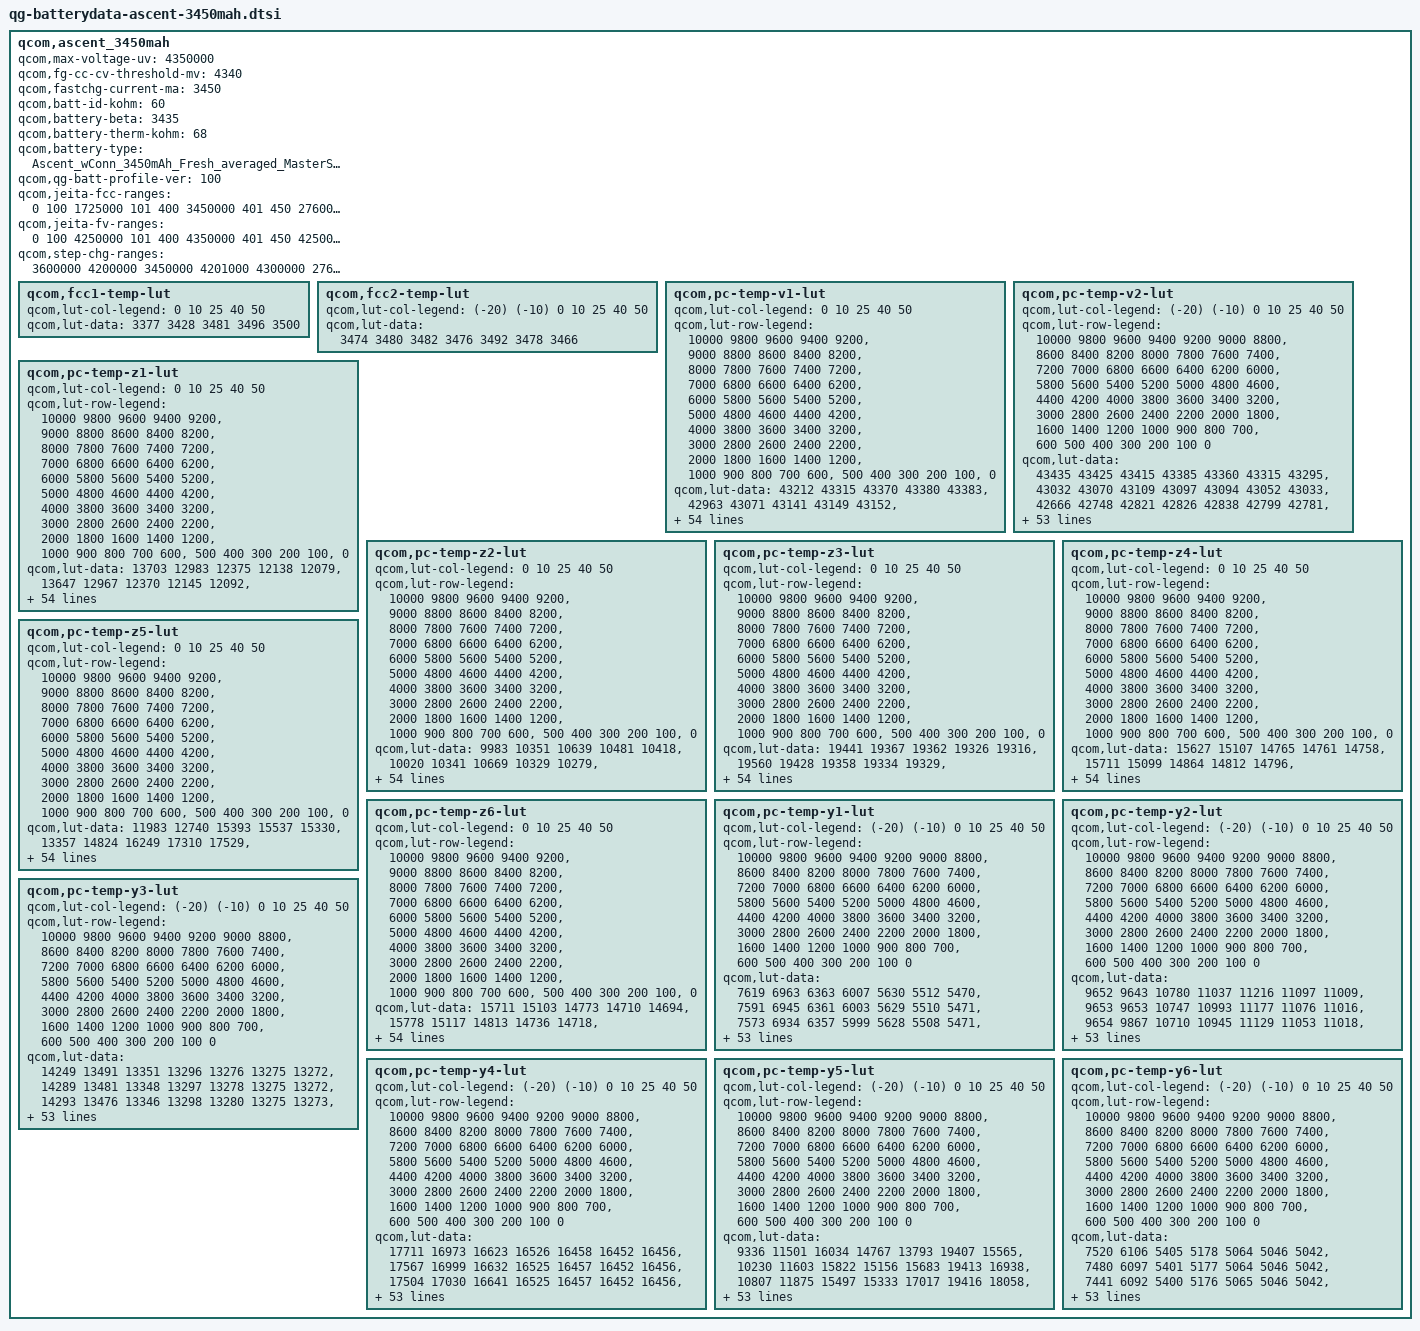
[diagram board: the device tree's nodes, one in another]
/* Copyright (c) 2018, The Linux Foundation. All rights reserved.
 *
 * This program is free software; you can redistribute it and/or modify
 * it under the terms of the GNU General Public License version 2 and
 * only version 2 as published by the Free Software Foundation.
 *
 * This program is distributed in the hope that it will be useful,
 * but WITHOUT ANY WARRANTY; without even the implied warranty of
 * MERCHANTABILITY or FITNESS FOR A PARTICULAR PURPOSE.  See the
 * GNU General Public License for more details.
 */

qcom,ascent_3450mah {
	/* Ascent_wConn_3450mAh_Fresh_averaged_MasterSlave_Feb7th2018 */
	qcom,max-voltage-uv = <4350000>;
	qcom,fg-cc-cv-threshold-mv = <4340>;
	qcom,fastchg-current-ma = <3450>;
	qcom,batt-id-kohm = <60>;
	qcom,battery-beta = <3435>;
	qcom,battery-therm-kohm = <68>;
	qcom,battery-type =
		"Ascent_wConn_3450mAh_Fresh_averaged_MasterSlave_Feb7th2018";
	qcom,qg-batt-profile-ver = <100>;

	qcom,jeita-fcc-ranges = <0   100  1725000
				101  400  3450000
				401  450  2760000>;
	qcom,jeita-fv-ranges = <0   100  4250000
				101 400  4350000
				401 450  4250000>;
	qcom,step-chg-ranges = <3600000  4200000  3450000
				4201000  4300000  2760000
				4301000  4350000  2070000>;

	qcom,fcc1-temp-lut {
		qcom,lut-col-legend = <0 10 25 40 50>;
		qcom,lut-data = <3377 3428 3481 3496 3500>;
	};

	qcom,fcc2-temp-lut {
		qcom,lut-col-legend = <(-20) (-10) 0 10 25 40 50>;
		qcom,lut-data = <3474 3480 3482 3476 3492 3478 3466>;
	};

	qcom,pc-temp-v1-lut {
		qcom,lut-col-legend = <0 10 25 40 50>;
		qcom,lut-row-legend = <10000 9800 9600 9400 9200>,
			<9000 8800 8600 8400 8200>,
			<8000 7800 7600 7400 7200>,
			<7000 6800 6600 6400 6200>,
			<6000 5800 5600 5400 5200>,
			<5000 4800 4600 4400 4200>,
			<4000 3800 3600 3400 3200>,
			<3000 2800 2600 2400 2200>,
			<2000 1800 1600 1400 1200>,
			<1000 900 800 700 600>,
			<500 400 300 200 100>,
			<0>;
		qcom,lut-data = <43212 43315 43370 43380 43383>,
			<42963 43071 43141 43149 43152>,
			<42723 42832 42902 42916 42922>,
			<42488 42597 42662 42683 42693>,
			<42262 42367 42430 42454 42465>,
			<42043 42143 42202 42225 42238>,
			<41832 41924 41976 41999 42013>,
			<41624 41709 41754 41775 41791>,
			<41419 41497 41536 41556 41571>,
			<41220 41288 41322 41341 41355>,
			<41039 41091 41113 41132 41143>,
			<40866 40911 40916 40928 40936>,
			<40676 40732 40729 40729 40734>,
			<40449 40526 40541 40538 40541>,
			<40230 40302 40340 40351 40355>,
			<40061 40115 40146 40170 40176>,
			<39918 39974 39984 40002 40007>,
			<39787 39846 39843 39845 39846>,
			<39672 39712 39697 39690 39689>,
			<39560 39579 39548 39536 39538>,
			<39426 39419 39388 39376 39384>,
			<39271 39170 39192 39187 39198>,
			<39112 38928 38961 38960 38967>,
			<38934 38809 38788 38776 38775>,
			<38764 38736 38674 38650 38646>,
			<38660 38665 38581 38546 38539>,
			<38589 38587 38491 38448 38439>,
			<38533 38513 38408 38359 38347>,
			<38487 38444 38334 38278 38263>,
			<38448 38381 38265 38204 38187>,
			<38407 38323 38204 38138 38118>,
			<38364 38269 38149 38078 38055>,
			<38322 38219 38099 38026 37999>,
			<38284 38175 38053 37975 37942>,
			<38249 38137 38014 37930 37889>,
			<38211 38098 37974 37884 37834>,
			<38174 38061 37930 37831 37767>,
			<38129 38020 37882 37771 37691>,
			<38055 37954 37816 37698 37610>,
			<37946 37848 37718 37605 37524>,
			<37825 37726 37602 37497 37426>,
			<37689 37595 37474 37372 37301>,
			<37541 37451 37332 37231 37156>,
			<37372 37290 37178 37080 36999>,
			<37271 37162 37061 36964 36886>,
			<37191 37093 36992 36897 36819>,
			<37157 37064 36970 36870 36798>,
			<37128 37039 36949 36844 36770>,
			<37084 37007 36903 36788 36714>,
			<36927 36851 36683 36562 36488>,
			<36555 36481 36290 36180 36108>,
			<36071 35999 35771 35687 35620>,
			<35450 35376 35098 35050 34994>,
			<34604 34523 34174 34184 34150>,
			<33275 33138 32725 32851 32862>,
			<30000 30000 30000 30000 30000>;
	};

	qcom,pc-temp-v2-lut {
		qcom,lut-col-legend = <(-20) (-10) 0 10 25 40 50>;
		qcom,lut-row-legend = <10000 9800 9600 9400 9200 9000 8800>,
			<8600 8400 8200 8000 7800 7600 7400>,
			<7200 7000 6800 6600 6400 6200 6000>,
			<5800 5600 5400 5200 5000 4800 4600>,
			<4400 4200 4000 3800 3600 3400 3200>,
			<3000 2800 2600 2400 2200 2000 1800>,
			<1600 1400 1200 1000 900 800 700>,
			<600 500 400 300 200 100 0>;
		qcom,lut-data = <43435 43425 43415 43385 43360 43315 43295>,
			<43032 43070 43109 43097 43094 43052 43033>,
			<42666 42748 42821 42826 42838 42799 42781>,
			<42342 42462 42555 42571 42594 42557 42541>,
			<42053 42208 42308 42333 42361 42326 42312>,
			<41788 41968 42072 42101 42133 42099 42086>,
			<41531 41736 41844 41872 41904 41872 41860>,
			<41298 41516 41625 41649 41680 41649 41637>,
			<41128 41303 41405 41431 41460 41430 41419>,
			<41009 41100 41186 41217 41243 41215 41204>,
			<40843 40896 40979 41012 41034 41005 40994>,
			<40462 40694 40796 40826 40840 40802 40789>,
			<40004 40482 40616 40642 40648 40604 40590>,
			<39736 40220 40407 40432 40445 40411 40399>,
			<39556 39903 40175 40199 40233 40222 40214>,
			<39382 39636 39954 39996 40043 40042 40036>,
			<39187 39443 39759 39844 39886 39877 39868>,
			<39001 39272 39570 39700 39736 39717 39706>,
			<38839 39091 39370 39511 39573 39556 39547>,
			<38695 38908 39162 39283 39399 39396 39391>,
			<38574 38742 38973 39072 39208 39217 39217>,
			<38477 38591 38806 38886 38975 38988 38994>,
			<38393 38460 38655 38721 38760 38766 38771>,
			<38314 38358 38519 38585 38613 38613 38614>,
			<38242 38274 38396 38468 38496 38494 38494>,
			<38176 38201 38287 38362 38390 38388 38387>,
			<38117 38138 38189 38265 38294 38291 38288>,
			<38062 38080 38106 38177 38206 38202 38198>,
			<38006 38027 38039 38096 38126 38120 38114>,
			<37953 37980 37983 38021 38051 38044 38037>,
			<37900 37934 37935 37954 37984 37976 37967>,
			<37847 37889 37895 37891 37921 37915 37905>,
			<37795 37843 37856 37838 37862 37856 37846>,
			<37742 37795 37815 37799 37803 37790 37781>,
			<37690 37746 37774 37768 37746 37720 37707>,
			<37635 37692 37727 37728 37685 37643 37621>,
			<37574 37633 37677 37677 37620 37554 37517>,
			<37509 37568 37618 37617 37550 37465 37411>,
			<37441 37491 37546 37548 37475 37387 37327>,
			<37368 37404 37459 37466 37395 37313 37256>,
			<37292 37310 37360 37369 37301 37226 37174>,
			<37209 37206 37243 37246 37187 37117 37069>,
			<37119 37103 37111 37106 37050 36988 36945>,
			<37020 37005 36964 36946 36900 36839 36796>,
			<36901 36909 36860 36837 36818 36761 36712>,
			<36762 36808 36782 36769 36775 36718 36673>,
			<36671 36746 36740 36732 36741 36690 36651>,
			<36552 36670 36688 36684 36692 36649 36612>,
			<36386 36553 36594 36591 36575 36542 36528>,
			<36157 36329 36380 36368 36272 36271 36278>,
			<35824 35961 35991 35957 35796 35833 35867>,
			<35340 35436 35452 35401 35193 35271 35340>,
			<34648 34709 34745 34680 34409 34550 34676>,
			<33623 33672 33759 33677 33330 33585 33791>,
			<31758 31857 32191 32244 31867 32001 32517>,
			<27623 28160 28896 29014 27510 28586 29617>;
	};

	qcom,pc-temp-z1-lut {
		qcom,lut-col-legend = <0 10 25 40 50>;
		qcom,lut-row-legend = <10000 9800 9600 9400 9200>,
			<9000 8800 8600 8400 8200>,
			<8000 7800 7600 7400 7200>,
			<7000 6800 6600 6400 6200>,
			<6000 5800 5600 5400 5200>,
			<5000 4800 4600 4400 4200>,
			<4000 3800 3600 3400 3200>,
			<3000 2800 2600 2400 2200>,
			<2000 1800 1600 1400 1200>,
			<1000 900 800 700 600>,
			<500 400 300 200 100>,
			<0>;
		qcom,lut-data = <13703 12983 12375 12138 12079>,
			<13647 12967 12370 12145 12092>,
			<13621 12953 12363 12143 12093>,
			<13606 12942 12357 12142 12093>,
			<13594 12927 12349 12140 12093>,
			<13585 12916 12342 12137 12093>,
			<13577 12905 12339 12136 12092>,
			<13569 12898 12337 12135 12092>,
			<13560 12896 12337 12135 12091>,
			<13551 12895 12339 12135 12091>,
			<13540 12896 12342 12136 12091>,
			<13527 12899 12342 12136 12091>,
			<13512 12901 12342 12137 12093>,
			<13488 12896 12342 12139 12095>,
			<13469 12887 12343 12141 12097>,
			<13469 12883 12347 12144 12098>,
			<13473 12891 12352 12147 12101>,
			<13478 12904 12360 12151 12103>,
			<13489 12912 12369 12155 12106>,
			<13502 12919 12378 12160 12109>,
			<13514 12927 12387 12165 12113>,
			<13525 12937 12396 12171 12117>,
			<13538 12948 12404 12177 12122>,
			<13555 12957 12412 12184 12127>,
			<13572 12965 12422 12189 12131>,
			<13578 12971 12431 12195 12135>,
			<13580 12978 12440 12200 12139>,
			<13582 12985 12448 12206 12143>,
			<13594 12992 12456 12212 12147>,
			<13613 13004 12464 12218 12151>,
			<13625 13010 12472 12224 12156>,
			<13631 13010 12479 12230 12160>,
			<13632 13010 12486 12237 12165>,
			<13627 13015 12494 12244 12171>,
			<13618 13033 12505 12253 12177>,
			<13619 13047 12517 12262 12183>,
			<13629 13056 12529 12271 12190>,
			<13640 13065 12541 12280 12196>,
			<13647 13068 12553 12290 12203>,
			<13654 13070 12565 12301 12210>,
			<13663 13071 12577 12311 12217>,
			<13678 13085 12588 12322 12224>,
			<13694 13098 12598 12332 12232>,
			<13718 13107 12607 12344 12239>,
			<13717 13110 12621 12356 12248>,
			<13717 13111 12638 12367 12256>,
			<13693 13110 12640 12374 12262>,
			<13712 13131 12642 12382 12269>,
			<13714 13118 12659 12395 12280>,
			<13717 13140 12677 12408 12291>,
			<13717 13160 12678 12422 12303>,
			<13740 13166 12691 12436 12316>,
			<13739 13183 12711 12456 12332>,
			<13754 13201 12735 12479 12355>,
			<13754 13201 12735 12479 12355>,
			<13754 13201 12735 12479 12355>;
	};

	qcom,pc-temp-z2-lut {
		qcom,lut-col-legend = <0 10 25 40 50>;
		qcom,lut-row-legend = <10000 9800 9600 9400 9200>,
			<9000 8800 8600 8400 8200>,
			<8000 7800 7600 7400 7200>,
			<7000 6800 6600 6400 6200>,
			<6000 5800 5600 5400 5200>,
			<5000 4800 4600 4400 4200>,
			<4000 3800 3600 3400 3200>,
			<3000 2800 2600 2400 2200>,
			<2000 1800 1600 1400 1200>,
			<1000 900 800 700 600>,
			<500 400 300 200 100>,
			<0>;
		qcom,lut-data = <9983 10351 10639 10481 10418>,
			<10020 10341 10669 10329 10279>,
			<10051 10333 10528 10319 10282>,
			<10083 10331 10397 10312 10281>,
			<10100 10329 10358 10299 10263>,
			<10094 10325 10328 10285 10234>,
			<10081 10303 10324 10279 10227>,
			<10069 10281 10328 10277 10237>,
			<10058 10278 10330 10276 10251>,
			<10050 10280 10326 10276 10266>,
			<10044 10285 10321 10281 10280>,
			<10039 10298 10323 10288 10285>,
			<10038 10310 10324 10308 10284>,
			<10045 10309 10318 10321 10285>,
			<10054 10304 10304 10319 10295>,
			<10056 10302 10291 10314 10309>,
			<10056 10312 10297 10316 10321>,
			<10058 10329 10320 10326 10335>,
			<10070 10353 10339 10334 10341>,
			<10090 10386 10349 10339 10346>,
			<10111 10400 10358 10343 10354>,
			<10138 10396 10373 10334 10340>,
			<10157 10388 10395 10289 10270>,
			<10169 10381 10400 10243 10212>,
			<10178 10372 10354 10197 10174>,
			<10183 10364 10306 10161 10144>,
			<10190 10352 10304 10160 10141>,
			<10194 10341 10307 10170 10149>,
			<10185 10335 10310 10181 10158>,
			<10169 10332 10311 10196 10169>,
			<10165 10332 10314 10216 10183>,
			<10168 10343 10327 10238 10202>,
			<10171 10357 10356 10267 10226>,
			<10175 10368 10381 10298 10253>,
			<10180 10376 10405 10333 10288>,
			<10183 10384 10422 10367 10326>,
			<10186 10393 10431 10393 10358>,
			<10189 10403 10438 10416 10387>,
			<10187 10410 10442 10437 10405>,
			<10181 10419 10455 10461 10418>,
			<10175 10423 10465 10476 10426>,
			<10164 10407 10466 10476 10430>,
			<10152 10385 10468 10474 10428>,
			<10142 10373 10453 10473 10402>,
			<10064 10371 10455 10479 10389>,
			<10173 10285 10486 10517 10402>,
			<10003 10290 10490 10530 10416>,
			<10151 10295 10531 10566 10477>,
			<10255 10515 10588 10612 10540>,
			<10077 10376 10556 10524 10421>,
			<9948 10240 10480 10454 10314>,
			<9854 10122 10384 10398 10256>,
			<9640 9998 10319 10342 10182>,
			<9440 9830 10255 10261 10065>,
			<9440 9830 10255 10261 10065>,
			<9440 9830 10255 10261 10065>;
	};

	qcom,pc-temp-z3-lut {
		qcom,lut-col-legend = <0 10 25 40 50>;
		qcom,lut-row-legend = <10000 9800 9600 9400 9200>,
			<9000 8800 8600 8400 8200>,
			<8000 7800 7600 7400 7200>,
			<7000 6800 6600 6400 6200>,
			<6000 5800 5600 5400 5200>,
			<5000 4800 4600 4400 4200>,
			<4000 3800 3600 3400 3200>,
			<3000 2800 2600 2400 2200>,
			<2000 1800 1600 1400 1200>,
			<1000 900 800 700 600>,
			<500 400 300 200 100>,
			<0>;
		qcom,lut-data = <19441 19367 19362 19326 19316>,
			<19560 19428 19358 19334 19329>,
			<19615 19467 19373 19341 19335>,
			<19645 19480 19383 19346 19340>,
			<19658 19487 19385 19351 19344>,
			<19657 19488 19387 19354 19347>,
			<19657 19486 19386 19355 19348>,
			<19655 19483 19384 19354 19347>,
			<19651 19481 19382 19352 19346>,
			<19647 19479 19380 19350 19345>,
			<19645 19477 19378 19347 19344>,
			<19642 19470 19377 19345 19342>,
			<19642 19464 19374 19345 19342>,
			<19642 19464 19372 19344 19341>,
			<19643 19467 19372 19343 19338>,
			<19639 19467 19372 19342 19336>,
			<19626 19460 19371 19340 19334>,
			<19615 19450 19369 19338 19332>,
			<19604 19448 19368 19337 19330>,
			<19596 19446 19368 19337 19328>,
			<19597 19447 19369 19337 19326>,
			<19605 19452 19372 19340 19328>,
			<19612 19460 19378 19350 19341>,
			<19619 19462 19386 19357 19350>,
			<19626 19464 19394 19361 19353>,
			<19627 19466 19401 19364 19355>,
			<19626 19472 19400 19364 19355>,
			<19624 19480 19398 19362 19352>,
			<19620 19480 19395 19359 19349>,
			<19615 19476 19391 19356 19346>,
			<19611 19473 19388 19353 19343>,
			<19609 19469 19384 19350 19340>,
			<19606 19466 19381 19347 19336>,
			<19604 19463 19379 19343 19332>,
			<19601 19461 19377 19338 19327>,
			<19597 19458 19375 19335 19324>,
			<19592 19454 19373 19334 19325>,
			<19587 19451 19370 19334 19329>,
			<19584 19448 19368 19334 19330>,
			<19582 19446 19366 19334 19328>,
			<19579 19443 19364 19334 19326>,
			<19575 19441 19362 19334 19326>,
			<19571 19438 19360 19334 19327>,
			<19565 19434 19359 19336 19329>,
			<19361 19423 19353 19335 19328>,
			<19262 19382 19344 19323 19324>,
			<19263 19371 19336 19321 19317>,
			<19261 19361 19332 19317 19313>,
			<19261 19273 19326 19317 19309>,
			<19262 19274 19335 19327 19319>,
			<19263 19303 19337 19330 19324>,
			<19263 19274 19357 19333 19327>,
			<19266 19275 19361 19337 19335>,
			<19272 19280 19368 19349 19345>,
			<19272 19280 19368 19349 19345>,
			<19272 19280 19368 19349 19345>;
	};

	qcom,pc-temp-z4-lut {
		qcom,lut-col-legend = <0 10 25 40 50>;
		qcom,lut-row-legend = <10000 9800 9600 9400 9200>,
			<9000 8800 8600 8400 8200>,
			<8000 7800 7600 7400 7200>,
			<7000 6800 6600 6400 6200>,
			<6000 5800 5600 5400 5200>,
			<5000 4800 4600 4400 4200>,
			<4000 3800 3600 3400 3200>,
			<3000 2800 2600 2400 2200>,
			<2000 1800 1600 1400 1200>,
			<1000 900 800 700 600>,
			<500 400 300 200 100>,
			<0>;
		qcom,lut-data = <15627 15107 14765 14761 14758>,
			<15711 15099 14864 14812 14796>,
			<15693 15080 14843 14798 14788>,
			<15530 15036 14821 14778 14775>,
			<15355 14952 14794 14760 14761>,
			<15246 14887 14764 14740 14745>,
			<15155 14845 14741 14726 14731>,
			<15085 14812 14721 14713 14719>,
			<15031 14784 14710 14705 14711>,
			<14985 14760 14705 14700 14707>,
			<14938 14745 14702 14697 14705>,
			<14895 14735 14696 14693 14702>,
			<14876 14729 14689 14688 14699>,
			<14872 14730 14686 14684 14697>,
			<14869 14735 14686 14681 14694>,
			<14856 14737 14686 14680 14692>,
			<14830 14720 14682 14677 14689>,
			<14808 14702 14673 14672 14684>,
			<14790 14701 14669 14669 14681>,
			<14778 14706 14676 14670 14679>,
			<14782 14717 14687 14675 14677>,
			<14805 14815 14716 14690 14685>,
			<14835 14927 14778 14733 14726>,
			<14898 14927 14803 14755 14750>,
			<14965 14883 14774 14738 14735>,
			<14974 14842 14741 14715 14712>,
			<14963 14813 14728 14705 14703>,
			<14950 14789 14721 14700 14699>,
			<14932 14778 14717 14696 14696>,
			<14910 14771 14715 14693 14692>,
			<14892 14767 14713 14691 14688>,
			<14878 14766 14712 14688 14683>,
			<14867 14765 14712 14684 14677>,
			<14856 14764 14710 14681 14673>,
			<14847 14763 14709 14676 14668>,
			<14838 14761 14706 14673 14666>,
			<14826 14756 14703 14673 14669>,
			<14816 14748 14700 14674 14680>,
			<14809 14744 14697 14674 14683>,
			<14804 14742 14695 14673 14677>,
			<14797 14739 14693 14671 14673>,
			<14787 14730 14687 14667 14673>,
			<14774 14718 14678 14663 14675>,
			<14753 14708 14673 14662 14682>,
			<14897 14683 14660 14653 14674>,
			<14965 14689 14638 14630 14635>,
			<14964 14694 14635 14621 14624>,
			<14958 14699 14630 14614 14617>,
			<14951 14794 14633 14616 14620>,
			<14945 14795 14637 14644 14655>,
			<14957 14769 14642 14654 14664>,
			<14968 14805 14636 14660 14668>,
			<14977 14809 14655 14668 14668>,
			<14993 14817 14684 14674 14665>,
			<14993 14817 14684 14674 14665>,
			<14993 14817 14684 14674 14665>;
	};

	qcom,pc-temp-z5-lut {
		qcom,lut-col-legend = <0 10 25 40 50>;
		qcom,lut-row-legend = <10000 9800 9600 9400 9200>,
			<9000 8800 8600 8400 8200>,
			<8000 7800 7600 7400 7200>,
			<7000 6800 6600 6400 6200>,
			<6000 5800 5600 5400 5200>,
			<5000 4800 4600 4400 4200>,
			<4000 3800 3600 3400 3200>,
			<3000 2800 2600 2400 2200>,
			<2000 1800 1600 1400 1200>,
			<1000 900 800 700 600>,
			<500 400 300 200 100>,
			<0>;
		qcom,lut-data = <11983 12740 15393 15537 15330>,
			<13357 14824 16249 17310 17529>,
			<14286 16482 17811 18377 18523>,
			<14945 17642 19175 19223 19510>,
			<15486 18555 20024 20275 20513>,
			<15957 19327 20723 21346 21540>,
			<16368 19918 21568 22345 22519>,
			<16781 20541 22514 23454 23469>,
			<17187 21683 23120 24074 24236>,
			<17674 23224 23449 23971 24698>,
			<18442 24060 23713 23757 25052>,
			<19483 24549 23914 23816 25554>,
			<20437 24925 24207 24637 26312>,
			<21361 25257 24451 25542 26851>,
			<22105 25909 24697 26092 27021>,
			<22478 26475 25087 26614 27131>,
			<22735 27141 26348 27394 27470>,
			<23076 28081 28954 28566 28331>,
			<23809 29715 30229 29356 28825>,
			<24938 32251 30431 29724 28646>,
			<27176 33544 30446 29885 28135>,
			<31932 33025 28578 28445 26783>,
			<35226 31860 23567 23249 22747>,
			<36819 29994 21621 20580 20432>,
			<37874 26035 23092 21806 21763>,
			<37147 24128 25214 23841 23948>,
			<34993 26078 27156 25488 25430>,
			<32825 29127 29386 27105 26647>,
			<30980 31187 31134 28441 27481>,
			<29376 32887 32400 29515 28206>,
			<28873 34208 33430 30375 28775>,
			<28786 35400 34311 31101 29161>,
			<28801 36250 35051 31824 29873>,
			<28836 36325 35497 32045 30283>,
			<28862 36122 35938 31861 30590>,
			<28907 35854 36221 31646 31106>,
			<28980 35186 35497 31570 32686>,
			<29132 34291 33694 31549 35494>,
			<29670 33796 32315 31543 36261>,
			<30652 33516 31332 31469 34185>,
			<30992 33114 30388 31412 32325>,
			<29938 32130 29262 32046 32870>,
			<29033 30867 28327 33225 34089>,
			<28928 29512 27958 34867 35083>,
			<16971 28826 27177 35407 35456>,
			<11113 18542 25875 28236 38118>,
			<11084 16735 22486 31621 32274>,
			<11037 15601 21798 36765 39261>,
			<11035 11499 20071 40032 37713>,
			<11055 11574 22201 35765 26327>,
			<11017 12415 21829 29484 22484>,
			<10951 11419 39496 26044 20817>,
			<10890 11348 40899 24307 20580>,
			<10822 11392 37952 25288 21070>,
			<10822 11392 37952 25288 21070>,
			<10822 11392 37952 25288 21070>;
	};

	qcom,pc-temp-z6-lut {
		qcom,lut-col-legend = <0 10 25 40 50>;
		qcom,lut-row-legend = <10000 9800 9600 9400 9200>,
			<9000 8800 8600 8400 8200>,
			<8000 7800 7600 7400 7200>,
			<7000 6800 6600 6400 6200>,
			<6000 5800 5600 5400 5200>,
			<5000 4800 4600 4400 4200>,
			<4000 3800 3600 3400 3200>,
			<3000 2800 2600 2400 2200>,
			<2000 1800 1600 1400 1200>,
			<1000 900 800 700 600>,
			<500 400 300 200 100>,
			<0>;
		qcom,lut-data = <15711 15103 14773 14710 14694>,
			<15778 15117 14813 14736 14718>,
			<15776 15120 14809 14733 14717>,
			<15702 15106 14804 14728 14716>,
			<15620 15065 14793 14722 14713>,
			<15561 15031 14779 14715 14707>,
			<15508 15007 14768 14709 14701>,
			<15467 14987 14758 14703 14696>,
			<15435 14971 14751 14698 14692>,
			<15407 14959 14748 14695 14689>,
			<15379 14949 14746 14692 14687>,
			<15353 14940 14743 14689 14685>,
			<15339 14935 14739 14687 14684>,
			<15332 14935 14736 14685 14682>,
			<15326 14938 14737 14684 14680>,
			<15316 14939 14738 14683 14678>,
			<15302 14930 14736 14681 14676>,
			<15293 14921 14733 14679 14673>,
			<15289 14921 14732 14677 14671>,
			<15286 14926 14736 14678 14670>,
			<15291 14936 14744 14682 14669>,
			<15312 14986 14761 14691 14674>,
			<15338 15040 14795 14718 14702>,
			<15373 15042 14808 14732 14717>,
			<15408 15027 14802 14727 14713>,
			<15415 15016 14795 14720 14706>,
			<15414 15011 14791 14717 14702>,
			<15412 15007 14788 14714 14699>,
			<15408 15006 14786 14712 14697>,
			<15402 15004 14785 14710 14694>,
			<15399 15004 14784 14708 14691>,
			<15398 15005 14784 14706 14688>,
			<15397 15006 14784 14704 14684>,
			<15397 15009 14784 14701 14680>,
			<15398 15012 14784 14699 14677>,
			<15400 15015 14785 14696 14674>,
			<15402 15016 14785 14697 14677>,
			<15405 15017 14786 14699 14684>,
			<15410 15020 14787 14700 14687>,
			<15416 15026 14789 14702 14685>,
			<15423 15031 14791 14703 14683>,
			<15430 15034 14791 14703 14684>,
			<15437 15037 14791 14704 14687>,
			<15444 15040 14792 14706 14693>,
			<15425 15039 14789 14704 14690>,
			<15419 15030 14781 14691 14673>,
			<15424 15030 14778 14688 14665>,
			<15425 15032 14777 14685 14661>,
			<15431 15036 14780 14688 14662>,
			<15438 15047 14792 14708 14685>,
			<15458 15060 14801 14718 14695>,
			<15477 15072 14815 14726 14702>,
			<15501 15088 14835 14737 14710>,
			<15534 15114 14862 14753 14720>,
			<15534 15114 14862 14753 14720>,
			<15534 15114 14862 14753 14720>;
	};

	qcom,pc-temp-y1-lut {
		qcom,lut-col-legend = <(-20) (-10) 0 10 25 40 50>;
		qcom,lut-row-legend = <10000 9800 9600 9400 9200 9000 8800>,
			<8600 8400 8200 8000 7800 7600 7400>,
			<7200 7000 6800 6600 6400 6200 6000>,
			<5800 5600 5400 5200 5000 4800 4600>,
			<4400 4200 4000 3800 3600 3400 3200>,
			<3000 2800 2600 2400 2200 2000 1800>,
			<1600 1400 1200 1000 900 800 700>,
			<600 500 400 300 200 100 0>;
		qcom,lut-data = <7619 6963 6363 6007 5630 5512 5470>,
			<7591 6945 6361 6003 5629 5510 5471>,
			<7573 6934 6357 5999 5628 5508 5471>,
			<7563 6929 6354 5995 5627 5506 5471>,
			<7558 6928 6353 5992 5626 5505 5470>,
			<7556 6928 6357 5988 5625 5503 5470>,
			<7563 6934 6366 5985 5624 5502 5469>,
			<7573 6942 6374 5981 5624 5501 5467>,
			<7583 6939 6374 5982 5623 5500 5467>,
			<7616 6920 6366 5984 5624 5499 5467>,
			<7634 6910 6360 5985 5624 5498 5466>,
			<7600 6919 6357 5980 5623 5498 5466>,
			<7557 6931 6356 5973 5622 5498 5465>,
			<7560 6935 6362 5973 5622 5499 5465>,
			<7590 6938 6380 5978 5625 5500 5466>,
			<7605 6939 6390 5981 5628 5501 5467>,
			<7608 6942 6389 5985 5631 5501 5468>,
			<7612 6946 6387 5990 5634 5502 5469>,
			<7604 6943 6388 5989 5637 5503 5470>,
			<7584 6932 6391 5988 5639 5506 5471>,
			<7570 6929 6394 5987 5643 5508 5472>,
			<7557 6957 6397 5989 5647 5510 5473>,
			<7546 6985 6400 5994 5653 5513 5475>,
			<7543 6976 6405 6001 5658 5515 5478>,
			<7542 6942 6414 6012 5663 5518 5480>,
			<7542 6928 6418 6018 5668 5522 5483>,
			<7552 6934 6419 6019 5674 5525 5486>,
			<7565 6942 6418 6020 5681 5529 5488>,
			<7569 6951 6418 6021 5687 5533 5491>,
			<7568 6972 6418 6023 5692 5537 5493>,
			<7564 6978 6418 6025 5698 5541 5497>,
			<7549 6971 6422 6028 5705 5545 5500>,
			<7534 6961 6425 6032 5712 5550 5504>,
			<7531 6947 6422 6038 5720 5554 5507>,
			<7529 6929 6416 6048 5727 5559 5509>,
			<7527 6925 6416 6055 5734 5563 5512>,
			<7537 6932 6428 6059 5741 5569 5516>,
			<7548 6939 6438 6062 5748 5575 5522>,
			<7546 6939 6433 6063 5757 5580 5526>,
			<7534 6942 6422 6064 5767 5585 5529>,
			<7527 6944 6417 6067 5775 5591 5533>,
			<7526 6946 6416 6077 5783 5596 5537>,
			<7530 6941 6418 6083 5787 5603 5541>,
			<7568 6923 6429 6090 5790 5610 5546>,
			<7559 6953 6428 6086 5808 5622 5555>,
			<7568 6932 6433 6091 5813 5631 5561>,
			<7570 6928 6433 6099 5818 5635 5565>,
			<7608 6933 6442 6113 5834 5640 5567>,
			<7652 6932 6430 6105 5835 5645 5571>,
			<7693 6936 6436 6106 5848 5654 5578>,
			<7737 6965 6440 6099 5858 5666 5585>,
			<7770 6990 6464 6110 5873 5684 5600>,
			<7830 7027 6445 6123 5887 5704 5613>,
			<7848 7064 6471 6136 5914 5726 5633>,
			<7848 7064 6471 6136 5914 5726 5633>,
			<7848 7064 6471 6136 5914 5726 5633>;
	};

	qcom,pc-temp-y2-lut {
		qcom,lut-col-legend = <(-20) (-10) 0 10 25 40 50>;
		qcom,lut-row-legend = <10000 9800 9600 9400 9200 9000 8800>,
			<8600 8400 8200 8000 7800 7600 7400>,
			<7200 7000 6800 6600 6400 6200 6000>,
			<5800 5600 5400 5200 5000 4800 4600>,
			<4400 4200 4000 3800 3600 3400 3200>,
			<3000 2800 2600 2400 2200 2000 1800>,
			<1600 1400 1200 1000 900 800 700>,
			<600 500 400 300 200 100 0>;
		qcom,lut-data = <9652 9643 10780 11037 11216 11097 11009>,
			<9653 9653 10747 10993 11177 11076 11016>,
			<9654 9867 10710 10945 11129 11053 11018>,
			<9655 10082 10673 10898 11080 11031 11018>,
			<9655 10246 10642 10860 11037 11010 11015>,
			<9655 10308 10624 10837 11007 10992 11010>,
			<9655 10281 10616 10826 10987 10977 10981>,
			<9655 10241 10610 10820 10968 10962 10937>,
			<9655 10275 10600 10816 10953 10942 10920>,
			<9655 10440 10586 10802 10939 10913 10908>,
			<9655 10531 10580 10792 10927 10894 10901>,
			<9654 10522 10610 10786 10915 10881 10897>,
			<9654 10502 10665 10780 10900 10869 10890>,
			<9653 10430 10721 10797 10878 10869 10877>,
			<9653 10226 10789 10873 10846 10876 10849>,
			<9653 10115 10817 10940 10834 10878 10831>,
			<9653 9949 10805 10988 10876 10871 10840>,
			<9653 9749 10791 11021 10939 10863 10860>,
			<9653 9704 10791 11014 10991 10869 10866>,
			<9653 9683 10795 10979 11041 10898 10870>,
			<9653 9677 10801 10965 11063 10936 10877>,
			<9653 9676 10808 10997 11078 11004 10940>,
			<9653 9676 10820 11042 11093 11066 11026>,
			<9652 9674 10836 11062 11099 11074 11055>,
			<9652 9670 10861 11077 11105 11063 11066>,
			<9652 9667 10915 11082 11111 11064 11068>,
			<9652 9665 11341 11085 11126 11092 11072>,
			<9652 9663 11748 11091 11149 11125 11083>,
			<9652 9661 11516 11099 11179 11148 11096>,
			<9652 9659 10816 11110 11217 11174 11118>,
			<9652 9658 10376 11118 11236 11190 11131>,
			<9652 9657 10155 11117 11245 11208 11140>,
			<9652 9656 10000 11109 11252 11224 11152>,
			<9652 9655 9892 11094 11259 11233 11175>,
			<9652 9654 9812 11060 11260 11250 11208>,
			<9652 9654 9762 11020 11250 11255 11218>,
			<9652 9653 9725 10915 11227 11244 11186>,
			<9652 9653 9701 10784 11207 11227 11146>,
			<9652 9653 9688 10695 11192 11211 11135>,
			<9651 9652 9678 10615 11172 11194 11131>,
			<9651 9652 9671 10480 11143 11192 11126>,
			<9651 9652 9665 10201 11106 11216 11112>,
			<9651 9651 9661 10108 11076 11220 11105>,
			<9651 9651 9658 10159 11042 11183 11120>,
			<9650 9651 9656 9965 10929 11157 11073>,
			<9650 9651 9654 9856 10889 11090 11023>,
			<9650 9651 9653 9796 10823 11057 10968>,
			<9649 9650 9653 9741 10794 11051 10955>,
			<9649 9650 9652 9696 10740 11029 10918>,
			<9649 9650 9652 9680 10652 10968 10907>,
			<9648 9650 9651 9670 10540 10916 10868>,
			<9648 9649 9651 9663 10397 10801 10776>,
			<9647 9648 9650 9657 10262 10712 10696>,
			<9647 9648 9650 9654 10448 10584 10596>,
			<9647 9648 9650 9654 10448 10584 10596>,
			<9647 9648 9650 9654 10448 10584 10596>;
	};

	qcom,pc-temp-y3-lut {
		qcom,lut-col-legend = <(-20) (-10) 0 10 25 40 50>;
		qcom,lut-row-legend = <10000 9800 9600 9400 9200 9000 8800>,
			<8600 8400 8200 8000 7800 7600 7400>,
			<7200 7000 6800 6600 6400 6200 6000>,
			<5800 5600 5400 5200 5000 4800 4600>,
			<4400 4200 4000 3800 3600 3400 3200>,
			<3000 2800 2600 2400 2200 2000 1800>,
			<1600 1400 1200 1000 900 800 700>,
			<600 500 400 300 200 100 0>;
		qcom,lut-data = <14249 13491 13351 13296 13276 13275 13272>,
			<14289 13481 13348 13297 13278 13275 13272>,
			<14293 13476 13346 13298 13280 13275 13273>,
			<14269 13476 13347 13300 13282 13276 13274>,
			<14223 13480 13349 13302 13283 13276 13274>,
			<14165 13486 13352 13303 13283 13276 13275>,
			<14057 13513 13358 13303 13283 13276 13275>,
			<13951 13546 13363 13304 13283 13276 13275>,
			<13946 13543 13365 13306 13283 13277 13275>,
			<13996 13505 13365 13310 13284 13278 13275>,
			<14024 13476 13366 13315 13285 13278 13276>,
			<13979 13465 13371 13319 13285 13278 13276>,
			<13920 13456 13377 13322 13285 13278 13276>,
			<13916 13446 13376 13322 13286 13278 13276>,
			<13935 13434 13369 13321 13288 13279 13277>,
			<13956 13428 13363 13320 13290 13279 13277>,
			<13974 13428 13359 13318 13291 13280 13278>,
			<13993 13428 13354 13316 13292 13282 13278>,
			<14013 13414 13349 13313 13292 13283 13279>,
			<14037 13377 13343 13308 13291 13283 13281>,
			<14068 13356 13338 13304 13290 13284 13281>,
			<14115 13351 13336 13301 13286 13280 13278>,
			<14171 13349 13333 13299 13283 13276 13274>,
			<14221 13354 13323 13298 13282 13275 13273>,
			<14271 13374 13301 13297 13281 13275 13273>,
			<14325 13397 13289 13297 13281 13275 13273>,
			<14385 13424 13273 13297 13280 13275 13273>,
			<14448 13457 13259 13297 13280 13275 13273>,
			<14513 13494 13259 13296 13280 13275 13273>,
			<14578 13537 13259 13296 13280 13275 13273>,
			<14647 13586 13260 13295 13280 13274 13272>,
			<14717 13644 13261 13291 13280 13274 13272>,
			<14792 13708 13262 13288 13279 13274 13272>,
			<14878 13777 13264 13289 13279 13274 13272>,
			<14972 13853 13268 13293 13279 13273 13272>,
			<15069 13939 13274 13295 13279 13273 13272>,
			<15166 14040 13285 13294 13279 13274 13272>,
			<15270 14153 13299 13292 13280 13274 13273>,
			<15386 14276 13317 13292 13279 13274 13273>,
			<15514 14412 13340 13293 13279 13274 13273>,
			<15658 14564 13372 13291 13279 13274 13273>,
			<15825 14738 13423 13271 13280 13275 13273>,
			<16019 14925 13493 13262 13280 13275 13273>,
			<16253 15128 13598 13261 13280 13274 13273>,
			<16581 15354 13729 13263 13279 13275 13274>,
			<16918 15547 13885 13266 13284 13276 13275>,
			<17576 15700 13996 13270 13284 13277 13277>,
			<18634 15883 14139 13280 13288 13279 13277>,
			<20075 16098 14305 13309 13290 13280 13277>,
			<22149 16340 14489 13343 13292 13280 13276>,
			<25271 16656 14726 13389 13294 13281 13277>,
			<29950 17634 15025 13481 13299 13283 13278>,
			<37310 19636 15401 13635 13309 13286 13283>,
			<47876 22946 16005 13899 13335 13293 13287>,
			<47876 22946 16005 13899 13335 13293 13287>,
			<47876 22946 16005 13899 13335 13293 13287>;
	};

	qcom,pc-temp-y4-lut {
		qcom,lut-col-legend = <(-20) (-10) 0 10 25 40 50>;
		qcom,lut-row-legend = <10000 9800 9600 9400 9200 9000 8800>,
			<8600 8400 8200 8000 7800 7600 7400>,
			<7200 7000 6800 6600 6400 6200 6000>,
			<5800 5600 5400 5200 5000 4800 4600>,
			<4400 4200 4000 3800 3600 3400 3200>,
			<3000 2800 2600 2400 2200 2000 1800>,
			<1600 1400 1200 1000 900 800 700>,
			<600 500 400 300 200 100 0>;
		qcom,lut-data = <17711 16973 16623 16526 16458 16452 16456>,
			<17567 16999 16632 16525 16457 16452 16456>,
			<17504 17030 16641 16525 16457 16452 16456>,
			<17504 17060 16652 16526 16457 16452 16456>,
			<17547 17082 16663 16528 16457 16452 16456>,
			<17613 17089 16674 16531 16457 16452 16456>,
			<17765 17077 16687 16535 16459 16452 16456>,
			<17948 17059 16701 16539 16462 16453 16456>,
			<18024 17098 16711 16545 16465 16453 16456>,
			<18066 17276 16720 16552 16468 16454 16457>,
			<18080 17396 16735 16563 16473 16455 16457>,
			<17811 17426 16824 16584 16480 16458 16458>,
			<17427 17443 16930 16612 16490 16461 16460>,
			<17319 17384 16951 16638 16498 16465 16462>,
			<17285 17155 16958 16663 16504 16470 16465>,
			<17245 17028 16959 16695 16515 16476 16469>,
			<17166 17014 16934 16758 16539 16486 16475>,
			<17085 17005 16887 16816 16571 16502 16486>,
			<17039 16980 16831 16800 16609 16530 16506>,
			<17007 16933 16754 16713 16656 16576 16541>,
			<16985 16886 16692 16635 16664 16593 16558>,
			<16968 16837 16644 16572 16570 16535 16521>,
			<16957 16797 16610 16522 16475 16468 16470>,
			<16954 16783 16607 16507 16460 16455 16458>,
			<16953 16776 16623 16498 16454 16451 16455>,
			<16953 16770 16632 16494 16453 16449 16454>,
			<16951 16765 16645 16493 16454 16449 16453>,
			<16951 16761 16659 16493 16455 16448 16453>,
			<16953 16761 16662 16492 16457 16449 16453>,
			<16959 16761 16663 16493 16461 16452 16454>,
			<16965 16762 16667 16493 16466 16456 16455>,
			<16974 16764 16677 16492 16474 16464 16461>,
			<16982 16767 16687 16492 16479 16471 16470>,
			<16985 16770 16690 16494 16478 16474 16476>,
			<16987 16775 16693 16500 16474 16474 16483>,
			<16990 16778 16693 16505 16467 16471 16482>,
			<16999 16782 16689 16508 16455 16458 16467>,
			<17010 16784 16685 16510 16448 16447 16453>,
			<17021 16783 16685 16511 16449 16450 16455>,
			<17033 16781 16683 16512 16452 16456 16465>,
			<17048 16779 16681 16517 16455 16459 16471>,
			<17066 16770 16670 16558 16460 16458 16470>,
			<17087 16768 16654 16579 16464 16456 16468>,
			<17112 16776 16634 16584 16465 16448 16452>,
			<17124 16801 16629 16593 16474 16448 16444>,
			<17066 16819 16647 16617 16493 16467 16470>,
			<17161 16856 16669 16641 16507 16488 16496>,
			<17324 16905 16699 16672 16536 16520 16521>,
			<17559 16944 16754 16675 16565 16529 16536>,
			<17893 16949 16780 16683 16555 16503 16488>,
			<18450 16941 16767 16681 16554 16495 16479>,
			<19496 17078 16794 16695 16582 16508 16485>,
			<21979 17565 16874 16751 16646 16545 16510>,
			<30091 19162 17124 16888 16859 16671 16581>,
			<30091 19162 17124 16888 16859 16671 16581>,
			<30091 19162 17124 16888 16859 16671 16581>;
	};

	qcom,pc-temp-y5-lut {
		qcom,lut-col-legend = <(-20) (-10) 0 10 25 40 50>;
		qcom,lut-row-legend = <10000 9800 9600 9400 9200 9000 8800>,
			<8600 8400 8200 8000 7800 7600 7400>,
			<7200 7000 6800 6600 6400 6200 6000>,
			<5800 5600 5400 5200 5000 4800 4600>,
			<4400 4200 4000 3800 3600 3400 3200>,
			<3000 2800 2600 2400 2200 2000 1800>,
			<1600 1400 1200 1000 900 800 700>,
			<600 500 400 300 200 100 0>;
		qcom,lut-data = <9336 11501 16034 14767 13793 19407 15565>,
			<10230 11603 15822 15156 15683 19413 16938>,
			<10807 11875 15497 15333 17017 19416 18058>,
			<11133 12285 15152 15352 17855 19416 18894>,
			<11279 12803 14881 15266 18259 19413 19416>,
			<11310 13403 14778 15128 18284 19405 19590>,
			<11059 14551 14807 14793 17405 18933 19301>,
			<10701 15710 14848 14419 16236 18269 18809>,
			<11143 15425 14688 14471 15943 18195 18561>,
			<13343 13533 13983 14951 15873 18327 18385>,
			<14582 12513 13556 15219 15744 18394 18198>,
			<13448 13803 13493 14892 15050 17832 17726>,
			<11924 15473 13460 14418 14306 16921 17099>,
			<11782 15394 13744 14254 14381 16318 16821>,
			<12065 14258 14851 14181 14869 15815 16673>,
			<12212 13562 15643 14199 15070 15556 16471>,
			<12106 13428 15965 14556 14786 15450 15954>,
			<11900 13274 16199 15160 14490 15387 15465>,
			<11618 12936 16398 15863 14755 15446 15449>,
			<11196 12423 16588 16824 15793 15777 15650>,
			<11019 11952 16732 17460 16919 16267 15980>,
			<11074 11476 16879 17821 18292 17600 16933>,
			<11141 11117 16964 18087 19430 19112 18163>,
			<11133 11033 16245 18242 19821 19838 19000>,
			<11069 11009 14141 18325 19945 20331 19696>,
			<11046 11024 12876 18331 19914 20756 20093>,
			<11109 11056 11798 18517 19842 21457 20297>,
			<11170 11084 10948 18759 19785 21999 20418>,
			<11161 11132 10879 18828 19716 21658 20286>,
			<11138 11232 10862 18868 19575 20509 19563>,
			<11111 11269 10868 18768 19409 19604 18813>,
			<11071 11345 11005 17096 19184 18920 18072>,
			<11039 11421 11165 15478 19049 18499 17524>,
			<11083 11456 11261 16038 19331 18661 17776>,
			<11207 11520 11350 17571 20041 19331 19034>,
			<11252 11543 11387 18037 20606 20274 20444>,
			<11213 11613 11553 17270 21412 23017 22060>,
			<11168 11678 11697 16300 21789 25208 23225>,
			<11151 11640 11640 15861 20914 24442 22731>,
			<11145 11545 11511 15530 19618 22425 21047>,
			<11154 11506 11463 14798 19274 21559 20283>,
			<11189 11457 11412 12697 19217 21506 20308>,
			<11250 11415 11500 11853 18717 21719 20486>,
			<11392 11368 11742 11779 17923 22443 22679>,
			<11471 11364 11818 11639 16687 21754 22971>,
			<11412 11379 11581 11310 17555 18408 18279>,
			<11284 11464 11576 11214 16686 17313 17483>,
			<10955 11729 11969 11315 17033 16467 15409>,
			<10501 12142 11899 11677 16717 15881 14424>,
			<10146 11979 11895 11966 17491 17177 15372>,
			<9743 11649 12007 11983 17478 18213 16253>,
			<9402 11017 11938 11964 17190 17836 15973>,
			<9188 10265 11845 11923 16780 17343 17751>,
			<8988 9626 11312 12185 16916 17400 17911>,
			<8988 9626 11312 12185 16916 17400 17911>,
			<8988 9626 11312 12185 16916 17400 17911>;
	};

	qcom,pc-temp-y6-lut {
		qcom,lut-col-legend = <(-20) (-10) 0 10 25 40 50>;
		qcom,lut-row-legend = <10000 9800 9600 9400 9200 9000 8800>,
			<8600 8400 8200 8000 7800 7600 7400>,
			<7200 7000 6800 6600 6400 6200 6000>,
			<5800 5600 5400 5200 5000 4800 4600>,
			<4400 4200 4000 3800 3600 3400 3200>,
			<3000 2800 2600 2400 2200 2000 1800>,
			<1600 1400 1200 1000 900 800 700>,
			<600 500 400 300 200 100 0>;
		qcom,lut-data = <7520 6106 5405 5178 5064 5046 5042>,
			<7480 6097 5401 5177 5064 5046 5042>,
			<7441 6092 5400 5176 5065 5046 5042>,
			<7405 6089 5400 5176 5066 5047 5043>,
			<7374 6088 5401 5176 5067 5047 5044>,
			<7350 6088 5403 5176 5067 5047 5044>,
			<7329 6090 5407 5176 5068 5047 5044>,
			<7314 6094 5413 5177 5068 5047 5044>,
			<7323 6102 5416 5178 5069 5047 5044>,
			<7367 6117 5418 5182 5071 5048 5044>,
			<7391 6129 5422 5187 5073 5049 5045>,
			<7291 6135 5450 5195 5075 5050 5045>,
			<7156 6139 5483 5204 5078 5051 5046>,
			<7138 6123 5488 5211 5081 5052 5047>,
			<7142 6059 5490 5218 5085 5054 5048>,
			<7144 6027 5490 5226 5089 5056 5050>,
			<7141 6030 5484 5243 5097 5060 5052>,
			<7136 6034 5472 5259 5107 5066 5055>,
			<7138 6032 5457 5253 5118 5075 5062>,
			<7150 6027 5435 5225 5131 5088 5073>,
			<7165 6025 5421 5201 5133 5093 5078>,
			<7194 6031 5414 5182 5104 5074 5065>,
			<7230 6042 5409 5169 5075 5052 5048>,
			<7265 6061 5410 5167 5071 5048 5044>,
			<7301 6095 5412 5166 5069 5047 5043>,
			<7340 6132 5415 5166 5069 5046 5042>,
			<7383 6169 5421 5168 5070 5047 5042>,
			<7430 6210 5431 5171 5071 5047 5042>,
			<7476 6254 5444 5175 5073 5048 5043>,
			<7523 6302 5464 5178 5075 5049 5043>,
			<7575 6354 5486 5181 5078 5050 5044>,
			<7633 6411 5511 5183 5081 5052 5046>,
			<7696 6471 5539 5185 5083 5055 5048>,
			<7764 6535 5569 5192 5084 5056 5050>,
			<7836 6602 5603 5205 5084 5056 5053>,
			<7911 6677 5640 5216 5084 5056 5053>,
			<7991 6759 5681 5225 5083 5053 5049>,
			<8076 6849 5727 5234 5083 5051 5046>,
			<8172 6948 5778 5244 5084 5052 5047>,
			<8278 7058 5835 5257 5087 5055 5050>,
			<8396 7178 5899 5273 5091 5057 5052>,
			<8531 7313 5971 5295 5095 5058 5052>,
			<8689 7461 6060 5322 5099 5058 5052>,
			<8881 7625 6170 5355 5104 5056 5049>,
			<9142 7801 6295 5404 5112 5059 5048>,
			<9395 7952 6438 5465 5127 5066 5057>,
			<9966 8083 6542 5513 5135 5074 5067>,
			<10874 8233 6666 5574 5150 5086 5075>,
			<12099 8404 6813 5646 5166 5090 5080>,
			<13825 8597 6972 5725 5172 5084 5066>,
			<16318 8831 7159 5819 5184 5085 5065>,
			<20019 9655 7408 5955 5214 5093 5070>,
			<25895 11356 7725 6149 5262 5110 5083>,
			<35348 14260 8288 6430 5374 5157 5109>,
			<35348 14260 8288 6430 5374 5157 5109>,
			<35348 14260 8288 6430 5374 5157 5109>;
	};
};
